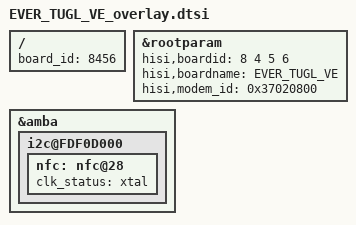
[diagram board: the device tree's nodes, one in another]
/**
 * Copyright (C) 2014 Hisilicon Ltd.
 *
 *  This program is free software; you can redistribute it and/or modify
 *  it under the terms of the GNU General Public License version 2 as
 *  publishhed by the Free Software Foundation.
 */


/include/ "EVER_TUGL_VD_overlay.dtsi"

/ {
    board_id = <8456>;
};
	&rootparam{
		hisi,boardid = <8 4 5 6>;
		hisi,boardname = "EVER_TUGL_VE";
		hisi,modem_id = <0x37020800>;
	};
        &amba {
            i2c@FDF0D000 {
                    nfc:nfc@28{
                            clk_status = "xtal";
                    };
            };
        };
